# tle984x register map
Vendor: Infineon; File version: 1.9.5
CPU: CM0 r2p1, little endian, no MPU, no FPU, 2 interrupt priority bits
Registers are 32-bit, read-write, reset 0x0 unless marked. A register's access mark holds for its fields unless they carry their own. Offsets are from the block's base; [hi:lo] are bit positions; {n}, {i} and the like mark numbered series; 'fields as' and 'values as' point back to an identical list.

## GPT12E — General purpose timer units (GPT12) registers
Base 0x40010000
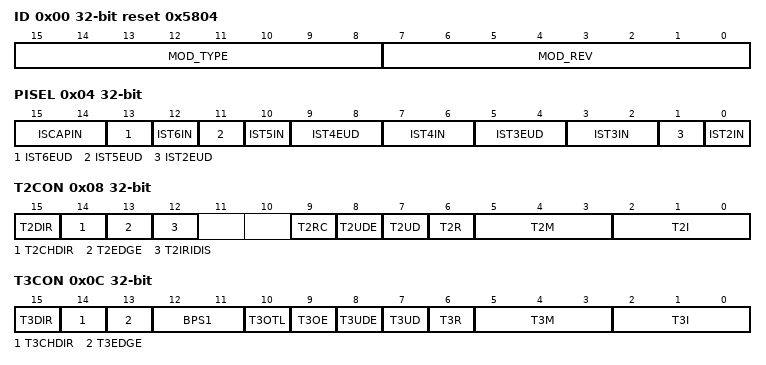
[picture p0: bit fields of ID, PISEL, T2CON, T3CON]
0x00 ID ro reset 0x5804 — Module identification register
  [15:8] MOD_TYPE — Module identification number
  [7:0] MOD_REV — Module revision number
0x04 PISEL — Port input select register
  [15:14] ISCAPIN — Input select for CAPIN
    0=CAPINA (Signal CAPINA is selected); 1=CAPINB (Signal CAPINB is selected); 2=CAPINC (Signal CAPINC (read trigger from T3) is selected); 3=CAPIND (Signal CAPIND (read trigger from T2 or T3 or T4) is selected)
  [13] IST6EUD — Input select for T6EUD
    0=T6EUDA (Signal T6EUDA is selected); 1=T6EUDB (Signal T6EUDB is selected)
  [12] IST6IN — Input select for T6IN
    0=T6INA (Signal T6INA is selected); 1=T6INB (Signal T6INB is selected)
  [11] IST5EUD — Input select for T5EUD
    0=T5EUDA (Signal T5EUDA is selected); 1=T5EUDB (Signal T5EUDB is selected)
  [10] IST5IN — Input select for T5IN
    0=T5INA (Signal T5INA is selected); 1=T5INB (Signal T5INB is selected)
  [9:8] IST4EUD — Input select for TEUD
    0=T4EUDA (Signal T4EUDA is selected); 1=T4EUDB (Signal T4EUDB is selected); 2=T4EUDC (Signal T4EUDC is selected); 3=T4EUDD (Signal T4EUDD is selected)
  [7:6] IST4IN — Input select for T4IN
    0=T4INA (Signal T4INA is selected); 1=T4INB (Signal T4INB is selected); 2=T4INC (Signal T4INC is selected); 3=T4IND (Signal T4IND is selected)
  [5:4] IST3EUD — Input select for T3EUD
    0=T3EUDA (Signal T3EUDA is selected); 1=T3EUDB (Signal T3EUDB is selected); 2=T3EUDC (Signal T3EUDC is selected); 3=T3EUDD (Signal T3EUDD is selected)
  [3:2] IST3IN — Input select for T3IN
    0=T3INA (Signal T3INA is selected); 1=T3INB (Signal T3INB is selected); 2=T3INC (Signal T3INC is selected); 3=T3IND (Signal T3IND is selected)
  [1] IST2EUD — Input select for T2EUD
    0=T2EUDA (Signal T2EUDA is selected); 1=T2EUDB (Signal T2EUDB is selected)
  [0] IST2IN — Input select for T2IN
    0=T2INA (Signal T2INA is selected); 1=T2INB (Signal T2INB is selected)
0x08 T2CON — Timer T2 control register
  [15] T2DIR ro — Timer T2 rotation direction
    0=UP (Timer T2 counts up); 1=DOWN (Timer T2 counts down)
  [14] T2CHDIR — Timer T2 count direction change
    0=NO_CHANGE (No change of count direction was detected); 1=CHANGE (A change of count direction was detected)
  [13] T2EDGE — Timer T2 edge detection
    0=NO_COUNT (No count edge was detected); 1=COUNT (A count edge was detected)
  [12] T2IRIDIS — Timer T2 interrupt disable
    0=ENABLED (Interrupt generation for T2CHDIR and T2EDGE interrupts in incremental interface mode is enabled); 1=DISABLED (Interrupt generation for T2CHDIR and T2EDGE interrupts in incremental interface mode is disabled)
  [9] T2RC — Timer T2 remote control
    0=T2R (Timer T2 is controlled by its own run bit T2R); 1=T3R (Timer T2 is controlled by the run bit T3R of core timer T3, not by bit T2R)
  [8] T2UDE — Timer T2 external up/down enable
    0=T2UD (Count direction is controlled by bit T2UD; input T2EUD is disconnected); 1=T2EUD (Count direction is controlled by input T2EUD)
  [7] T2UD — Timer T2 up/down control
    0=UP (Timer T2 counts up); 1=DOWN (Timer T2 counts down)
  [6] T2R — Timer T2 input run bit
    0=STOP (Timer T2 stops); 1=RUN (Timer T2 runs)
  [5:3] T2M — Timer T2 input mode control
    0=TIMER_MODE; 1=COUNTER_MODE; 2=GATED_LOW (Gated timer mode with gate active low); 3=GATED_HIGH (Gated timer mode with gate active high); 4=RELOAD_MODE; 5=CAPTURE_MODE; 6=INCREMENTAL_INTERFACE_MODE (Rotation detection mode); 7=INCREMENTAL_INTERFACE_MODE (Edge detection mode)
  [2:0] T2I — Timer T2 input parameter selection
0x0C T3CON — Timer T3 control register
  [15] T3DIR ro — Timer T3 rotation direction flag
    0=UP (Timer T3 counts up); 1=DOWN (Timer T3 counts down)
  [14] T3CHDIR — Timer T3 count direction change flag
    values as T2CON.T2CHDIR
  [13] T3EDGE — Timer T3 edge detection flag
    values as T2CON.T2EDGE
  [12:11] BPS1 — GPT1 block prescaler control
    0=fGPT/8; 1=fGPT/4; 2=fGPT/32; 3=fGPT/16
  [10] T3OTL — Timer T3 overflow toggle latch
  [9] T3OE — Overflow/underflow output enable
    0=DISABLED (Alternate output function disabled); 1=T3OUT (State of T3 toggle latch is output on pin T3OUT)
  [8] T3UDE — Timer T3 external up/down enable
    0=T3UD (Count direction is controlled by bit T3UD; input T3EUD is disconnected); 1=T3EUD (Count direction is controlled by input T3EUD)
  [7] T3UD — Timer T3 up/down control
    0=UP (Timer T3 counts up); 1=DOWN (Timer T3 counts down)
  [6] T3R — Timer T3 input run bit
    0=STOP (Timer T3 stops); 1=RUN (Timer T3 runs)
  [5:3] T3M — Timer T3 input mode control
    0=TIMER_MODE; 1=COUNTER_MODE; 2=GATED_LOW (Gated timer mode with gate active low); 3=GATED_HIGH (Gated timer mode with gate active high); 6=INCREMENTAL_INTERFACE_MODE (Rotation detection mode); 7=INCREMENTAL_INTERFACE_MODE (Edge detection mode)
  [2:0] T3I — Timer T3 input parameter selection
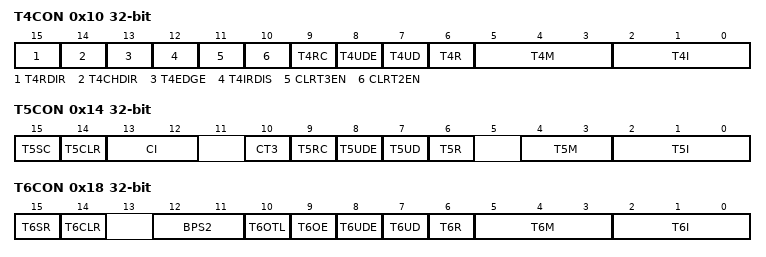
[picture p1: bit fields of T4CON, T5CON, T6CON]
0x10 T4CON — Timer T4 control register
  [15] T4RDIR ro — Timer T4 rotation direction
    0=UP (Timer T4 counts up); 1=DOWN (Timer T4 counts down)
  [14] T4CHDIR — Timer T4 count direction change
    0=NO_CHANGE (No change in count direction was detected); 1=CHANGE (A change in count direction was detected)
  [13] T4EDGE — Timer T4 edge direction
    values as T2CON.T2EDGE
  [12] T4IRDIS — Timer T4 interrupt disable
    0=ENABLED (Interrupt generation for T4CHDIR and T4EDGE interrupts in incremental interface mode is enabled); 1=DISABLED (Interrupt generation for T4CHDIR and T4EDGE interrupts in incremental interface mode is disabled)
  [11] CLRT3EN — Clear timer T3 enable
    0=NO_EFFECT (No effect of T4IN on timer T3); 1=CLEAR (A falling edge on T4In clears timer T3)
  [10] CLRT2EN — Clear timer T2 enable
    0=NO_EFFECT (No effect of T4EUD on timer T2); 1=CLEAR (A falling edge on T4EUD clears timer T2)
  [9] T4RC — Timer T4 remote control
    0=T4R (Timer T4 is controlled by its own run bit T4R); 1=T3R (Timer T4 is controlled by the run bit T3R of core timer T3, but not by bit T4R)
  [8] T4UDE — Timer T4 external up/down enable
    0=T4UD (Count direction is controlled by bit T4UD; input T4EUD is disconnected); 1=T4EUD (Count direction is controlled by input T4EUD)
  [7] T4UD — Timer T4 up/down control
    0=UP (Timer T4 counts up); 1=DOWN (Timer T4 counts down)
  [6] T4R — Timer T4 input run bit
    0=STOP (Timer T4 stops); 1=RUN (Timer T4 runs)
  [5:3] T4M — Timer T4 mode control (basic operating mode)
    values as T2CON.T2M
  [2:0] T4I — Timer T4 input parameter selection
0x14 T5CON — Timer T5 control register
  [15] T5SC — Timer T5 capture mode enable
    0=DISABLED (Capture into register CAPREL disabled); 1=ENABLED (Capture into register CAPREL enabled)
  [14] T5CLR — Timer T5 clear enable bit
    0=NOT_CLEARED (Timer T5 is not cleared on a capture event); 1=CLEARED (Timer T5 is cleared on a capture event)
  [13:12] CI — Register CAPREL capture trigger selection
    0=DISABLED (Capture disabled); 1=POSITIVE (Positive transition (rising edge) on CAPIN); 2=NEGATIVE (Negative transition (falling edge) on CAPIN or any transition on T3EUD); 3=ANY (Any transition (rising or falling edge) on CAPIN or any transition on T3IN or T3EUD)
  [10] CT3 — Timer T3 capture trigger enable
    0=CAPIN (Capture trigger from input line CAPIN); 1=T3IN (Capture trigger from T3 input lines T3IN and/or T3EUD)
  [9] T5RC — Timer T5 remote control
    0=T5R (Timer T5 is controlled by its own run bit T5R); 1=T6R (Timer T5 is controlled by the run bit T6R of core timer T6, not by bit T5R)
  [8] T5UDE — Timer T5 external up/down enable
    0=T5UD (Count direction is controlled by bit T5UD; input T5EUD is disconnected); 1=T5EUD (Count direction is controlled by input T5EUD)
  [7] T5UD — Timer T5 up/down control
    0=UP (Timer T5 counts up); 1=DOWN (Timer T5 counts down)
  [6] T5R — Timer T5 run bit
    0=STOP (Timer T5 stops); 1=RUN (Timer T5 runs)
  [4:3] T5M — Timer T5 input mode control
    0=TIMER_MODE; 1=COUNTER_MODE; 2=GATED_LOW (Gated timer mode with gate active low); 3=GATED_HIGH (Gated timer mode with gate active high)
  [2:0] T5I — Timer T5 input parameter selection
0x18 T6CON — Timer T6 control register
  [15] T6SR — Timer T6 reload mode enable
    0=DISABLED (Reload from register CAPREL disabled); 1=ENABLED (Reload from register CAPREL enabled)
  [14] T6CLR — Timer T6 clear enable bit
    0=NOT_CLEARED (Timer T6 is not cleared on a capture event); 1=CLEARED (Timer T6 is cleared on a capture event)
  [12:11] BPS2 — GPT2 block prescaler control
    0=fGPT/4; 1=fGPT/2; 2=fGPT/16; 3=fGPT/8
  [10] T6OTL — Timer T6 overflow toggle latch
  [9] T6OE — Overflow/underflow output enable
    0=DISABLED (Alternate output function disabled); 1=T6OUT (State of T6 toggle latch is output on pin T6OUT)
  [8] T6UDE — Timer T6 external up/down enable
    0=T6UD (Count direction is controlled by bit T6UD; input T6EUD is disconnected); 1=T6EUD (Count direction is controlled by input T6EUD)
  [7] T6UD — Timer T6 up/down control
    0=UP (Timer T3 counts up); 1=DOWN (Timer T3 counts down)
  [6] T6R — Timer T6 input run bit
    0=STOP (Timer T3 stops); 1=RUN (Timer T3 runs)
  [5:3] T6M — Timer T6 mode control
    values as T5CON.T5M
  [2:0] T6I — Timer T6 input parameter selection
0x1C CAPREL — Capture/reload register
  [15:0] CAPREL — Current reload value or captured value
{0x18+4i} T{i} (i=2..4) — Timer T{i} count register
  [15:0] T{i} — Timer T{i} current value
0x2C T5 — Timer 5 count register
  [15:0] T5 — Timer T5 current value
0x30 T6 — Timer 6 count register
  [15:0] T6 — Timer T6 current value
